VERSION ""

NS_ :

BS_:

BU_: VCU ZC

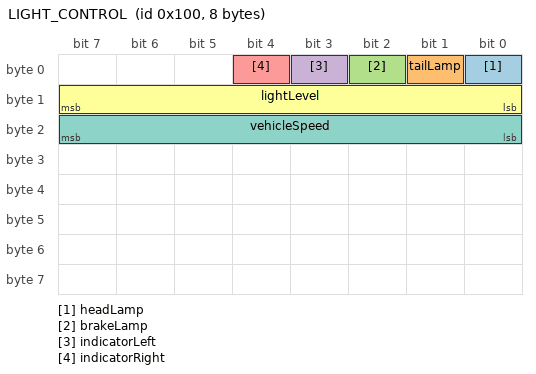
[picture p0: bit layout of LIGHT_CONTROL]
BO_ 256 LIGHT_CONTROL: 8 VCU
 SG_ headLamp : 0|1@1+ (1,0) [0|1] "" ZC
 SG_ tailLamp : 1|1@1+ (1,0) [0|1] "" ZC
 SG_ brakeLamp : 2|1@1+ (1,0) [0|1] "" ZC
 SG_ indicatorLeft : 3|1@1+ (1,0) [0|1] "" ZC
 SG_ indicatorRight : 4|1@1+ (1,0) [0|1] "" ZC
 SG_ lightLevel : 8|8@1+ (1,0) [0|255] "" ZC
 SG_ vehicleSpeed : 16|8@1+ (1,0) [0|255] "" ZC

CM_ BO_ 256 "Light control message";
CM_ SG_ 256 headLamp "Headlamp status (0=off, 1=on)";
